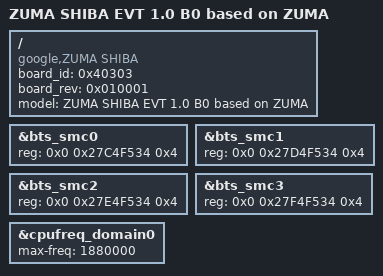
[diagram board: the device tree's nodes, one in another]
// SPDX-License-Identifier: GPL-2.0-only
/*
 * Shiba board device tree source
 *
 * Copyright 2023 Google LLC
 */

/dts-v1/;
/plugin/;

#include "zuma-shiba-common.dtsi"
#include "zuma-shusky-wcharger.dtsi"

/ {
	board_id = <0x40303>;
	board_rev = <0x010001>;
	fragment@boardbase {
		target-path = "/";
		__overlay__ {
			model = "ZUMA SHIBA EVT 1.0 B0 based on ZUMA";
			compatible = "google,ZUMA SHIBA", "google,ZUMA";
		};
	};
};

/* sync from zuma-b0.dts:
 * pa/2357080 28b25e825 arm64/dts: zuma: cpu: change CPU max freq for B0
 */
&bts_smc0 {
	reg = <0x0 0x27C4F534 0x4>;
};

&bts_smc1 {
	reg = <0x0 0x27D4F534 0x4>;
};

&bts_smc2 {
	reg = <0x0 0x27E4F534 0x4>;
};

&bts_smc3 {
	reg = <0x0 0x27F4F534 0x4>;
};

&cpufreq_domain0 {
	max-freq = <1880000>;
};
